# EFR32FG23B010F512IM48 register map
Vendor: Silicon Labs; Series: EFR32; File version: C
CPU: CM33 r0p4, little endian, MPU, FPU, DSP, VTOR, 4 interrupt priority bits, 8 SAU regions
Registers are 32-bit, read-write, reset 0x0 unless marked. A register's access mark holds for its fields unless they carry their own. Offsets are from the block's base; [hi:lo] are bit positions; {n}, {i} and the like mark numbered series.

## SYSCFG_NS — SYSCFG_NS Registers
Base 0x5007C000
Same registers: SYSCFG_S 0x4007C000
0x04 IPVERSION ro reset 0x2
  [31:0] IPVERSION — New BitField
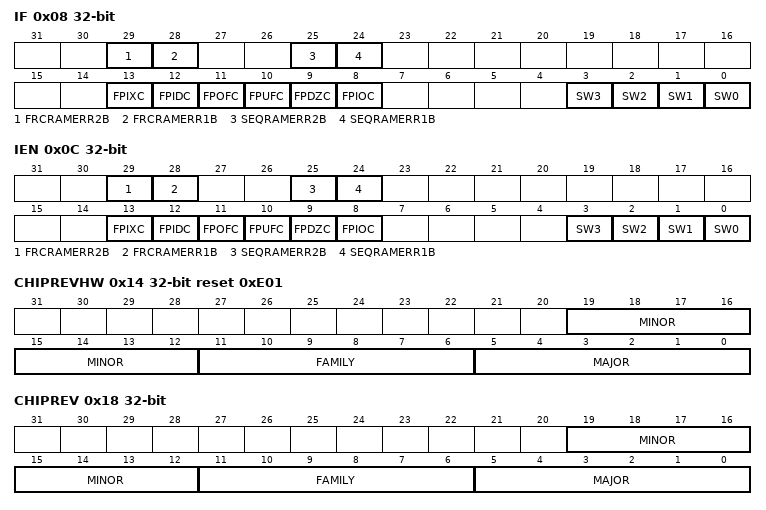
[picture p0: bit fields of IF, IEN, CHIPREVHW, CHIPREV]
0x08 IF — Read to get system status.
  [29] FRCRAMERR2B — FRCRAM Error 2-bit Interrupt Flag
  [28] FRCRAMERR1B — FRCRAM Error 1-bit Interrupt Flag
  [25] SEQRAMERR2B — SEQRAM Error 2-bit Interrupt Flag
  [24] SEQRAMERR1B — SEQRAM Error 1-bit Interrupt Flag
  [13] FPIXC — FPU Inexact interrupt flag
  [12] FPIDC — FPU Input denormal interrupt flag
  [11] FPOFC — FPU Overflow interrupt flag
  [10] FPUFC — FPU Underflow interrupt flag
  [9] FPDZC — FPU Divide by zero interrupt flag
  [8] FPIOC — FPU Invalid Operation interrupt flag
  [n] SW{n} (n=0..3) — Software Interrupt Flag
0x0C IEN — Write to enable interrupts.
  [29] FRCRAMERR2B — FRCRAM Error 2-bit Interrupt Enable
  [28] FRCRAMERR1B — FRCRAM Error 1-bit Interrupt Enable
  [25] SEQRAMERR2B — SEQRAM Error 2-bit Interrupt Enable
  [24] SEQRAMERR1B — SEQRAM Error 1-bit Interrupt Enable
  [13] FPIXC — FPU Inexact Interrupt Enable
  [12] FPIDC — FPU Input denormal Interrupt Enable
  [11] FPOFC — FPU Overflow Interrupt Enable
  [10] FPUFC — FPU Underflow Interrupt Enable
  [9] FPDZC — FPU Divide by zero Interrupt Enable
  [8] FPIOC — FPU Invalid Operation Interrupt Enable
  [n] SW{n} (n=0..3) — Software Interrupt Enable
0x14 CHIPREVHW reset 0xE01 — Read to get the hard-wired chip revision.
  [19:12] MINOR — Hardwired Chip Revision Minor value
  [11:6] FAMILY — Hardwired Chip Family value
  [5:0] MAJOR — Hardwired Chip Revision Major value
0x18 CHIPREV — Read to get the chip revision programmed by feature configuration.
  [19:12] MINOR — Chip Revision Minor value
  [11:6] FAMILY — Chip Family value
    26=PG23 (Product is in PG23 family); 56=FG23 (Product is in FG23 family); 57=ZG23 (Product is in ZG23 family); 58=SG23 (Product is in SG23 family)
  [5:0] MAJOR — Chip Revision Major value
0x24 CFGSYSTIC — Configure the source of the system tick for the M33.
  [0] SYSTICEXTCLKEN — SysTick External Clock Enable
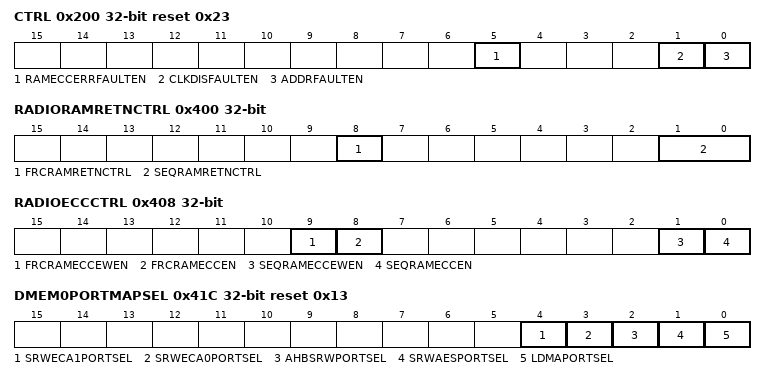
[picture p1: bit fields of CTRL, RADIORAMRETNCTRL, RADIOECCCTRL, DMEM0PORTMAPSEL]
0x200 CTRL reset 0x23 — Configure to provide general RAM configuration.
  [5] RAMECCERRFAULTEN — Two bit ECC error bus fault response ena
  [1] CLKDISFAULTEN — Disabled Clkbus Bus Fault Enable
  [0] ADDRFAULTEN — Invalid Address Bus Fault Response Enabl
0x208 DMEM0RETNCTRL — Configure to provide general RAM retention configuration.
  [2:0] RAMRETNCTRL — DMEM0 blockset retention control
    0=ALLON (None of the RAM blocks powered down); 4=BLK3 (Power down RAM block 3 (address range 0x2000C000-0x20010000)); 6=BLK2TO3 (Power down RAM blocks 2 and above (address range 0x20008000-0x20010000)); 7=BLK1TO3 (Power down RAM blocks 1 and above (address range 0x20004000-0x20010000))
0x30C RAMBIASCONF reset 0x2 — Configure RAM bias configure bits.
  [3:0] RAMBIASCTRL — RAM Bias Control
    0=No (None); 1=VSB100 (Voltage Source Bias 100mV); 2=VSB200 (Voltage Source Bias 200mV); 4=VSB300 (Voltage Source Bias 300mV); 8=VSB400 (Voltage Source Bias 400mV)
0x400 RADIORAMRETNCTRL — Configure SEQRAM Retention controls.
  [8] FRCRAMRETNCTRL — FRCRAM Retention Control
    0=ALLON (FRCRAM not powered down); 1=ALLOFF (Power down FRCRAM)
  [1:0] SEQRAMRETNCTRL — SEQRAM Retention Control
    0=ALLON (SEQRAM not powered down); 1=BLK0 (Power down SEQRAM block 0); 2=BLK1 (Power down SEQRAM block 1); 3=ALLOFF (Power down all SEQRAM blocks)
0x408 RADIOECCCTRL — Configure to set RAM ECC control.
  [9] FRCRAMECCEWEN — FRCRAM ECC Error Writeback Enable
  [8] FRCRAMECCEN — FRCRAM ECC Enable
  [1] SEQRAMECCEWEN — SEQRAM ECC Error Writeback Enable
  [0] SEQRAMECCEN — SEQRAM ECC Enable
0x410 SEQRAMECCADDR ro — Read to get status of the SEQRAM ECC error address.
  [31:0] SEQRAMECCADDR — SEQRAM ECC Address
0x414 FRCRAMECCADDR ro — Read to get status of the FRCRAM ECC error address.
  [31:0] FRCRAMECCADDR — FRCRAM ECC Error Address
0x418 ICACHERAMRETNCTRL — Configure Host ICACHERAM retention configuration.
  [0] RAMRETNCTRL — ICACHERAM Retention control
    0=ALLON (None of the Host ICACHE RAM blocks powered down); 1=ALLOFF (Power down all Host ICACHE RAM blocks)
0x41C DMEM0PORTMAPSEL reset 0x13 — Configure DMEM0 port remap selection.
  [4] SRWECA1PORTSEL — SRWECA1 portmap selection
  [3] SRWECA0PORTSEL — SRWECA0 portmap selection
  [2] AHBSRWPORTSEL — AHBSRW portmap selection
  [1] SRWAESPORTSEL — SRWAES portmap selection
  [0] LDMAPORTSEL — LDMA portmap selection
0x600 ROOTDATA0 — Generic data space for user to pass to root, e.g., address of struct in mem
  [31:0] DATA
0x604 ROOTDATA1 — Generic data space for user to pass to root, e.g., address of struct in mem
  [31:0] DATA
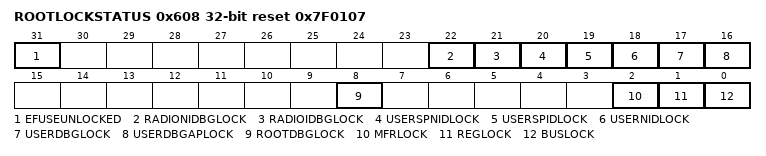
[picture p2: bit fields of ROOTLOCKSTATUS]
0x608 ROOTLOCKSTATUS ro reset 0x7F0107 — This register returns the status of the SE managed locks.
  [31] EFUSEUNLOCKED
  [22] RADIONIDBGLOCK — Radio Non-invasive Debug Lock
  [21] RADIOIDBGLOCK — Radio Invasive Debug Lock
  [20] USERSPNIDLOCK — User Secure Non-invasive Debug Lock
  [19] USERSPIDLOCK — User Secure Invasive Debug Lock
  [18] USERNIDLOCK — User Non-invasive Debug Lock
  [17] USERDBGLOCK — User Invasive Debug Lock
  [16] USERDBGAPLOCK — User Debug Access Port Lock
  [8] ROOTDBGLOCK — Root Debug Lock
  [2] MFRLOCK — Manufacture Lock
  [1] REGLOCK — Register Lock
  [0] BUSLOCK
0x60C ROOTSESWVERSION — SE Software version
  [31:0] SWVERSION
